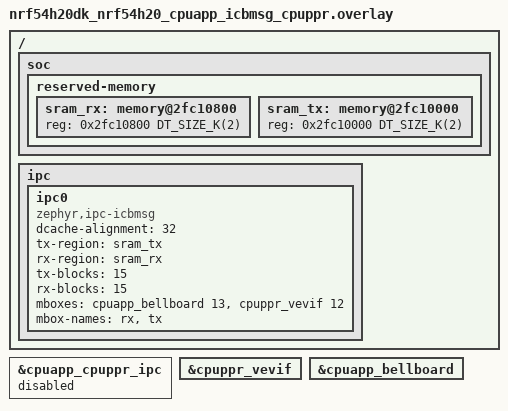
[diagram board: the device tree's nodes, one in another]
/*
 * Copyright (c) 2026 Nordic Semiconductor ASA
 *
 * SPDX-License-Identifier: Apache-2.0
 */

#include "nrf54h20dk_nrf54h20_cpuapp_common.dtsi"

/delete-node/ &ipc0;

&cpuapp_cpuppr_ipc {
	status = "disabled";
};

/ {
	soc {
		reserved-memory {
			#address-cells = <1>;
			#size-cells = <1>;

			sram_rx: memory@2fc10800 {
				reg = <0x2fc10800 DT_SIZE_K(2)>;
			};

			sram_tx: memory@2fc10000 {
				reg = <0x2fc10000 DT_SIZE_K(2)>;
			};
		};
	};

	ipc {
		ipc0: ipc0 {
			compatible = "zephyr,ipc-icbmsg";
			dcache-alignment = <32>;
			tx-region = <&sram_tx>;
			rx-region = <&sram_rx>;
			tx-blocks = <15>;
			rx-blocks = <15>;
			mboxes = <&cpuapp_bellboard 13>, <&cpuppr_vevif 12>;
			mbox-names = "rx", "tx";
			status = "okay";
		};
	};
};

&cpuppr_vevif {
	status = "okay";
};

&cpuapp_bellboard {
	status = "okay";
};
